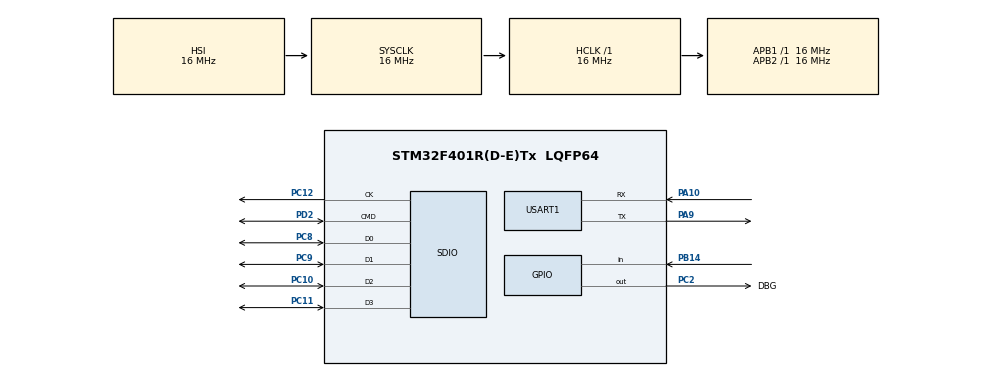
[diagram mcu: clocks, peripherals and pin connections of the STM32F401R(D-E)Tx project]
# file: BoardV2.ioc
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FATFS.BSP.number=1
FATFS0.BSP.STBoard=false
FATFS0.BSP.api=Unknown
FATFS0.BSP.i2caddr=0
FATFS0.BSP.instance=PB14
FATFS0.BSP.ip=GPIO
FATFS0.BSP.mode=Input
FATFS0.BSP.name=Detect_SDIO
FATFS0.BSP.solution=PB14
Mcu.Family=STM32F4
Mcu.Name=STM32F401R(D-E)Tx
Mcu.Package=LQFP64
NVIC.PriorityGroup=NVIC_PRIORITYGROUP_4
PA10.Mode=Asynchronous
PA10.Signal=USART1_RX
PA9.Mode=Asynchronous
PA9.Signal=USART1_TX
PB14.Signal=GPIO_Input
PC10.Mode=SD_4_bits_Wide_bus
PC10.Signal=SDIO_D2
PC11.Mode=SD_4_bits_Wide_bus
PC11.Signal=SDIO_D3
PC12.Mode=SD_4_bits_Wide_bus
PC12.Signal=SDIO_CK
PC2.GPIO_Label=DBG
PC2.Signal=GPIO_Output
PC8.Mode=SD_4_bits_Wide_bus
PC8.Signal=SDIO_D0
PC9.Mode=SD_4_bits_Wide_bus
PC9.Signal=SDIO_D1
PD2.Mode=SD_4_bits_Wide_bus
PD2.Signal=SDIO_CMD
ProjectManager.HeapSize=0x200
ProjectManager.StackSize=0x400
ProjectManager.TargetToolchain=STM32CubeIDE
RCC.AHBFreq_Value=16000000
RCC.APB1Freq_Value=16000000
RCC.APB2Freq_Value=16000000
RCC.CortexFreq_Value=16000000
RCC.HSE_VALUE=25000000
RCC.HSI_VALUE=16000000
RCC.LSE_VALUE=32768
RCC.SYSCLKFreq_VALUE=16000000
RCC.VCOOutputFreq_Value=192000000
USART1.VirtualMode=VM_ASYNC
VP_FATFS_VS_SDIO.Mode=SDIO
board=custom

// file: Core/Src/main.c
/* USER CODE BEGIN Header */
/**
  ******************************************************************************
  * @file           : main.c
  * @brief          : Main program body
  ******************************************************************************
  * @attention
  *
  * <h2><center>&copy; Copyright (c) 2020 STMicroelectronics.
  * All rights reserved.</center></h2>
  *
  * This software component is licensed by ST under BSD 3-Clause license,
  * the "License"; You may not use this file except in compliance with the
  * License. You may obtain a copy of the License at:
  *                        opensource.org/licenses/BSD-3-Clause
  *
  ******************************************************************************
  */
/* USER CODE END Header */
#include "main.h"
#include "fatfs.h"

SD_HandleTypeDef hsd;

UART_HandleTypeDef huart1;

FRESULT res;
FATFS SDFatFs;
FIL logFile;

void SystemClock_Config(void);
static void MX_GPIO_Init(void);
static void MX_SDIO_SD_Init(void);
static void MX_USART1_UART_Init(void);

void write(char text[]){
    for(int i = 0; i < sizeof(text); i++){
        HAL_UART_Transmit(&huart1, text[i], 1, HAL_MAX_DELAY);
    }
}

int main(void)
{

  /* MCU Configuration--------------------------------------------------------*/

  /* Reset of all peripherals, Initializes the Flash interface and the Systick. */
  HAL_Init();

  /* Configure the system clock */
  SystemClock_Config();

  /* Initialize all configured peripherals */
  MX_GPIO_Init();
  MX_SDIO_SD_Init();
  MX_USART1_UART_Init();
  MX_FATFS_Init();
  /* USER CODE BEGIN 2 */

  res = BSP_SD_Init();

  HAL_UART_Init(&huart1);

  HAL_UART_Transmit(&huart1, "hello\n", 6, HAL_MAX_DELAY);

  res = f_mount(&SDFatFs, "", 1);

  res = f_open(&logFile, "log.txt", 'w');

  res = f_puts("no way this works?", &logFile);

  f_close(&logFile);

  /* USER CODE END 2 */

  /* Infinite loop */
  while (1)
  {
    HAL_UART_Transmit(&huart1, "L", 1, HAL_MAX_DELAY);

  }
}

void SystemClock_Config(void)
{
  RCC_OscInitTypeDef RCC_OscInitStruct = {0};
  RCC_ClkInitTypeDef RCC_ClkInitStruct = {0};

  /** Configure the main internal regulator output voltage
  */
  __HAL_RCC_PWR_CLK_ENABLE();
  __HAL_PWR_VOLTAGESCALING_CONFIG(PWR_REGULATOR_VOLTAGE_SCALE2);
  /** Initializes the RCC Oscillators according to the specified parameters
  * in the RCC_OscInitTypeDef structure.
  */
  RCC_OscInitStruct.OscillatorType = RCC_OSCILLATORTYPE_HSI;
  RCC_OscInitStruct.HSIState = RCC_HSI_ON;
  RCC_OscInitStruct.HSICalibrationValue = RCC_HSICALIBRATION_DEFAULT;
  RCC_OscInitStruct.PLL.PLLState = RCC_PLL_ON;
  RCC_OscInitStruct.PLL.PLLSource = RCC_PLLSOURCE_HSI;
  RCC_OscInitStruct.PLL.PLLM = 16;
  RCC_OscInitStruct.PLL.PLLN = 192;
  RCC_OscInitStruct.PLL.PLLP = RCC_PLLP_DIV2;
  RCC_OscInitStruct.PLL.PLLQ = 4;
  if (HAL_RCC_OscConfig(&RCC_OscInitStruct) != HAL_OK)
  {
    Error_Handler();
  }
  /** Initializes the CPU, AHB and APB buses clocks
  */
  RCC_ClkInitStruct.ClockType = RCC_CLOCKTYPE_HCLK|RCC_CLOCKTYPE_SYSCLK
                              |RCC_CLOCKTYPE_PCLK1|RCC_CLOCKTYPE_PCLK2;
  RCC_ClkInitStruct.SYSCLKSource = RCC_SYSCLKSOURCE_HSI;
  RCC_ClkInitStruct.AHBCLKDivider = RCC_SYSCLK_DIV1;
  RCC_ClkInitStruct.APB1CLKDivider = RCC_HCLK_DIV1;
  RCC_ClkInitStruct.APB2CLKDivider = RCC_HCLK_DIV1;

  if (HAL_RCC_ClockConfig(&RCC_ClkInitStruct, FLASH_LATENCY_0) != HAL_OK)
  {
    Error_Handler();
  }
}

static void MX_SDIO_SD_Init(void)
{

  hsd.Instance = SDIO;
  hsd.Init.ClockEdge = SDIO_CLOCK_EDGE_RISING;
  hsd.Init.ClockBypass = SDIO_CLOCK_BYPASS_DISABLE;
  hsd.Init.ClockPowerSave = SDIO_CLOCK_POWER_SAVE_DISABLE;
  hsd.Init.BusWide = SDIO_BUS_WIDE_1B;
  hsd.Init.HardwareFlowControl = SDIO_HARDWARE_FLOW_CONTROL_DISABLE;
  hsd.Init.ClockDiv = 0;

}

static void MX_USART1_UART_Init(void)
{

  huart1.Instance = USART1;
  huart1.Init.BaudRate = 115200;
  huart1.Init.WordLength = UART_WORDLENGTH_8B;
  huart1.Init.StopBits = UART_STOPBITS_1;
  huart1.Init.Parity = UART_PARITY_NONE;
  huart1.Init.Mode = UART_MODE_TX_RX;
  huart1.Init.HwFlowCtl = UART_HWCONTROL_NONE;
  huart1.Init.OverSampling = UART_OVERSAMPLING_16;
  if (HAL_UART_Init(&huart1) != HAL_OK)
  {
    Error_Handler();
  }

}

static void MX_GPIO_Init(void)
{
  GPIO_InitTypeDef GPIO_InitStruct = {0};

  /* GPIO Ports Clock Enable */
  __HAL_RCC_GPIOC_CLK_ENABLE();
  __HAL_RCC_GPIOB_CLK_ENABLE();
  __HAL_RCC_GPIOA_CLK_ENABLE();
  __HAL_RCC_GPIOD_CLK_ENABLE();

  /*Configure GPIO pin Output Level */
  HAL_GPIO_WritePin(DBG_GPIO_Port, DBG_Pin, GPIO_PIN_RESET);

  /*Configure GPIO pin : DBG_Pin */
  GPIO_InitStruct.Pin = DBG_Pin;
  GPIO_InitStruct.Mode = GPIO_MODE_OUTPUT_PP;
  GPIO_InitStruct.Pull = GPIO_NOPULL;
  GPIO_InitStruct.Speed = GPIO_SPEED_FREQ_LOW;
  HAL_GPIO_Init(DBG_GPIO_Port, &GPIO_InitStruct);

  /*Configure GPIO pin : PB14 */
  GPIO_InitStruct.Pin = GPIO_PIN_14;
  GPIO_InitStruct.Mode = GPIO_MODE_INPUT;
  GPIO_InitStruct.Pull = GPIO_NOPULL;
  HAL_GPIO_Init(GPIOB, &GPIO_InitStruct);

}

void Error_Handler(void)
{
}

/************************ (C) COPYRIGHT STMicroelectronics *****END OF FILE****/
